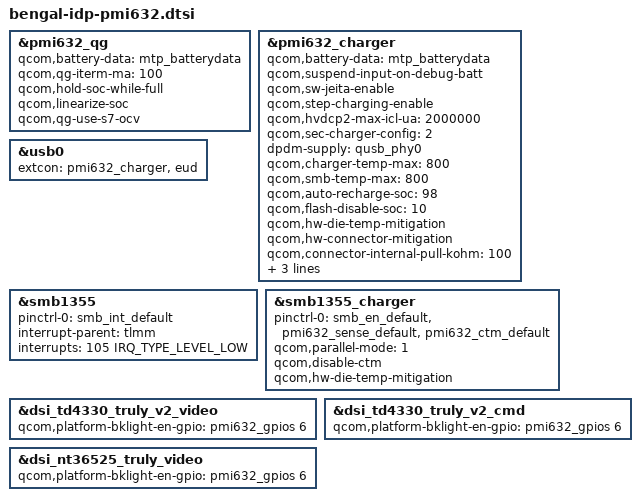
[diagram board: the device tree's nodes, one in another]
#include "bengal-pmi632.dtsi"

&pmi632_qg {
	qcom,battery-data = <&mtp_batterydata>;
	qcom,qg-iterm-ma = <100>;
	qcom,hold-soc-while-full;
	qcom,linearize-soc;
	qcom,qg-use-s7-ocv;
};

&pmi632_charger {
	qcom,battery-data = <&mtp_batterydata>;
	qcom,suspend-input-on-debug-batt;
	qcom,sw-jeita-enable;
	qcom,step-charging-enable;
	qcom,hvdcp2-max-icl-ua = <2000000>;
	/* SMB1355 only */
	qcom,sec-charger-config = <2>;
	dpdm-supply = <&qusb_phy0>;
	qcom,charger-temp-max = <800>;
	qcom,smb-temp-max = <800>;
	qcom,auto-recharge-soc = <98>;
	qcom,flash-disable-soc = <10>;
	qcom,hw-die-temp-mitigation;
	qcom,hw-connector-mitigation;
	qcom,connector-internal-pull-kohm = <100>;
	qcom,float-option = <1>;
	qcom,thermal-mitigation = <3000000 2500000
			2000000 1500000 1000000 500000>;
};

&usb0 {
	extcon = <&pmi632_charger>, <&eud>;
};

&smb1355 {
	pinctrl-names = "default";
	pinctrl-0 = <&smb_int_default>;
	interrupt-parent = <&tlmm>;
	interrupts = <105 IRQ_TYPE_LEVEL_LOW>;
	status = "ok";
};

&smb1355_charger {
	pinctrl-names = "default";
	pinctrl-0 = <&smb_en_default &pmi632_sense_default &pmi632_ctm_default>;
	qcom,parallel-mode = <1>;
	qcom,disable-ctm;
	qcom,hw-die-temp-mitigation;
	status = "ok";
};

&dsi_td4330_truly_v2_video {
	qcom,platform-bklight-en-gpio = <&pmi632_gpios 6 0>;
};

&dsi_td4330_truly_v2_cmd {
	qcom,platform-bklight-en-gpio = <&pmi632_gpios 6 0>;
};

&dsi_nt36525_truly_video {
	qcom,platform-bklight-en-gpio = <&pmi632_gpios 6 0>;
};

